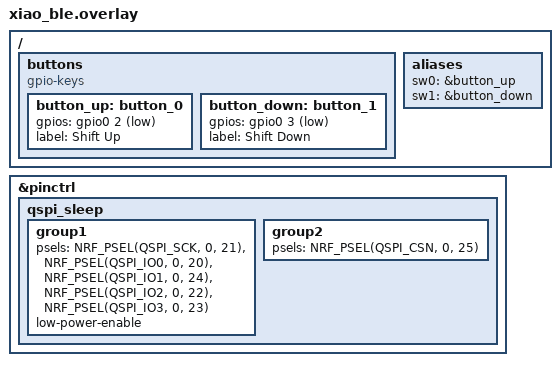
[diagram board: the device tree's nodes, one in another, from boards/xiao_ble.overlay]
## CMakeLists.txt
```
cmake_minimum_required(VERSION 3.20.0)
find_package(Zephyr REQUIRED HINTS $ENV{ZEPHYR_BASE})
project(nxs-controller)
target_sources(app PRIVATE
	src/main.c
	src/nxs_wireless_client.c
	src/debug_led.c
)
```

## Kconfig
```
menu "NXS Remote Application"

config APP_DEBUG_LED
	bool "Enable LED indication for shift command results (debug only)"
	default n
	help
	  シフトアップ/ダウンの成功・失敗をオンボードRGB LEDの点滅で示す。
	  GPIO操作が増えるため、省電力を優先する通常ビルドでは無効のままにする。

endmenu

source "Kconfig.zephyr"
```

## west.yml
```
manifest:
  remotes:
    - name: zephyrproject-rtos
      url-base: https://github.com/zephyrproject-rtos
  projects:
    - name: zephyr
      remote: zephyrproject-rtos
      revision: v4.4.2
      import: true
```

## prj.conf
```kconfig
CONFIG_GPIO=y

CONFIG_BT=y
CONFIG_BT_CENTRAL=y
CONFIG_BT_GATT_CLIENT=y
CONFIG_BT_MAX_CONN=1
CONFIG_BT_DEVICE_NAME="NXS-Cont"

CONFIG_POWEROFF=y
CONFIG_HWINFO=y
CONFIG_PM=y
CONFIG_PM_DEVICE=y

CONFIG_FLASH=y
```

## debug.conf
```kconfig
CONFIG_APP_DEBUG_LED=y
```

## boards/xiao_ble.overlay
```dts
#include <zephyr/dt-bindings/gpio/gpio.h>
#include <zephyr/dt-bindings/pinctrl/nrf-pinctrl.h>

/ {
	buttons {
		compatible = "gpio-keys";

		button_up: button_0 {
			gpios = <&gpio0 2 (GPIO_PULL_UP | GPIO_ACTIVE_LOW)>;
			label = "Shift Up";
		};

		button_down: button_1 {
			gpios = <&gpio0 3 (GPIO_PULL_UP | GPIO_ACTIVE_LOW)>;
			label = "Shift Down";
		};
	};

	aliases {
		sw0 = &button_up;
		sw1 = &button_down;
	};
};

&pinctrl {
    qspi_sleep: qspi_sleep {
        group1 {
            psels = <NRF_PSEL(QSPI_SCK, 0, 21)>,
                    <NRF_PSEL(QSPI_IO0, 0, 20)>,
                    <NRF_PSEL(QSPI_IO1, 0, 24)>,
                    <NRF_PSEL(QSPI_IO2, 0, 22)>,
                    <NRF_PSEL(QSPI_IO3, 0, 23)>;
            low-power-enable;
        };
        group2 {
            psels = <NRF_PSEL(QSPI_CSN, 0, 25)>;
        };
    };
};
```

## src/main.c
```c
#include <zephyr/kernel.h>
#include <zephyr/device.h>
#include <zephyr/drivers/gpio.h>
#include <zephyr/drivers/hwinfo.h>
#include <zephyr/pm/device.h>
#include <zephyr/sys/poweroff.h>
#include <zephyr/bluetooth/bluetooth.h>

#include "nxs_wireless_client.h"
#include "nxs_macaddr.h"
#include "debug_led.h"

#define NON_WAKEUP_RESET_REASON (RESET_PIN | RESET_SOFTWARE | RESET_POR | RESET_DEBUG)

static const struct gpio_dt_spec btn_up   = GPIO_DT_SPEC_GET(DT_ALIAS(sw0), gpios);
static const struct gpio_dt_spec btn_down = GPIO_DT_SPEC_GET(DT_ALIAS(sw1), gpios);

#if DT_NODE_EXISTS(DT_NODELABEL(p25q16h))
static const struct device *ext_flash = DEVICE_DT_GET(DT_NODELABEL(p25q16h));
#endif

static void arm_wakeup_and_poweroff(void)
{
    gpio_pin_configure_dt(&btn_up, GPIO_INPUT);
    gpio_pin_configure_dt(&btn_down, GPIO_INPUT);
    gpio_pin_interrupt_configure_dt(&btn_up, GPIO_INT_LEVEL_ACTIVE);
    gpio_pin_interrupt_configure_dt(&btn_down, GPIO_INT_LEVEL_ACTIVE);

#if DT_NODE_EXISTS(DT_NODELABEL(p25q16h))
    /* XIAOのオンボードQSPIフラッシュを明示的にディープパワーダウン。
       やらないとSystem OFF中も~1mA食われ続ける */
    if (device_is_ready(ext_flash)) {
        pm_device_action_run(ext_flash, PM_DEVICE_ACTION_SUSPEND);
    }
#endif

    hwinfo_clear_reset_cause();
    sys_poweroff();
}

int main(void)
{
    uint32_t reset_cause = 0;
    hwinfo_get_reset_cause(&reset_cause);

    if (reset_cause & NON_WAKEUP_RESET_REASON) {
        /* 書き込み直後・通常リセット。何もせずSystem OFFへ */
        arm_wakeup_and_poweroff();
        return 0;
    }

    /* GPIOによるSystem OFFからの復帰 = ボタン押下起床 */
    gpio_pin_configure_dt(&btn_up, GPIO_INPUT);
    gpio_pin_configure_dt(&btn_down, GPIO_INPUT);

    bool up   = gpio_pin_get_dt(&btn_up) > 0;
    bool down = gpio_pin_get_dt(&btn_down) > 0;

    if (up || down) {
        bt_enable(NULL);
        nxs_client_init(NXS_MAC, NXS_PIN);
        debug_led_init();

        int retry = 3;
        bool ok = false;
        while (retry-- && !ok) {
            ok = up ? nxs_connect_up_disconnect()
                     : nxs_connect_down_disconnect();
        }
        printk("shift %s: %s\n", up ? "up" : "down", ok ? "ok" : "failed");
        debug_led_shift_result(up, ok);
    }

    arm_wakeup_and_poweroff();
    return 0;
}
```

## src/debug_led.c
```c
#include "debug_led.h"

#if defined(CONFIG_APP_DEBUG_LED)

#include <zephyr/kernel.h>
#include <zephyr/drivers/gpio.h>

static const struct gpio_dt_spec led_red   = GPIO_DT_SPEC_GET(DT_ALIAS(led0), gpios);
static const struct gpio_dt_spec led_green = GPIO_DT_SPEC_GET(DT_ALIAS(led1), gpios);
static const struct gpio_dt_spec led_blue  = GPIO_DT_SPEC_GET(DT_ALIAS(led2), gpios);

void debug_led_init(void)
{
    gpio_pin_configure_dt(&led_red, GPIO_OUTPUT_INACTIVE);
    gpio_pin_configure_dt(&led_green, GPIO_OUTPUT_INACTIVE);
    gpio_pin_configure_dt(&led_blue, GPIO_OUTPUT_INACTIVE);
}

static void blink(const struct gpio_dt_spec *led, int times, int on_ms, int off_ms)
{
    for (int i = 0; i < times; i++) {
        gpio_pin_set_dt(led, 1);
        k_msleep(on_ms);
        gpio_pin_set_dt(led, 0);
        if (i + 1 < times) {
            k_msleep(off_ms);
        }
    }
}

void debug_led_shift_result(bool up, bool ok)
{
    if (!ok) {
        blink(&led_red, 3, 100, 100);   /* 失敗: 赤3回点滅（上下共通） */
        return;
    }
    /* 成功: 方向で色を分ける（アップ=緑、ダウン=青） */
    blink(up ? &led_green : &led_blue, 1, 300, 0);
}

#else /* !CONFIG_APP_DEBUG_LED */

void debug_led_init(void) {}
void debug_led_shift_result(bool up, bool ok) {}

#endif
```

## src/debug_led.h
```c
#pragma once
#include <stdbool.h>

void debug_led_init(void);
void debug_led_shift_result(bool up, bool ok);
```

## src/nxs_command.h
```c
#define BLE_CMD_GET_LIST 0x0000
#define BLE_CMD_ADD_DEVICE 0x0001
#define BLE_CMD_REMOVE_DEVICE 0x0002
#define BLE_CMD_SET_PIN 0x0003
#define BLE_CMD_BLINK_LED 0x0004
#define BLE_CMD_SET_BIKENET 0x0005
#define BLE_CMD_RESET_BIKENET 0x0006
#define BLE_CMD_DISCONNECT_DEVICE 0x0007
#define BLE_CMD_RECONNECT_DEVICE 0x0008   
#define BLE_CMD_SET_NAME 0x0009
#define BLE_CMD_CALIBRATE 0x000B
#define BLE_CMD_SET_DEV_CONFIG 0x000C
#define BLE_CMD_INCREMENT_MOVE 0x000D
#define BLE_CMD_ABSOLUTE_MOVE 0x000E
#define BLE_CMD_UPDATE_POSITION 0x000F
#define BLE_CMD_SHIFT_UP 0x0010
#define BLE_CMD_SHIFT_DOWN 0x0011
#define BLE_CMD_MOVE_TO_COG 0x0012
#define BLE_CMD_GET_POSITION 0x0013
#define BLE_CMD_WRITE_BUTTON_MAP 0x0014
#define BLE_CMD_READ_BUTTON_MAP 0x0015
#define BLE_CMD_SET_MOTOR_PARAMS 0x0016
#define BLE_CMD_GET_MOTOR_PARAMS 0x0017
#define BLE_CMD_GET_SKIP_TABLE 0x0018
#define BLE_CMD_MOTOR_HOME 0x0019
#define BLE_CMD_SET_SKIP_TABLE 0x001A
#define BLE_CMD_SET_FRONT_CONFIG 0x001B
#define BLE_CMD_GET_FRONT_CONFIG 0x001C
#define BLE_CMD_SET_REAR_COG_INFO 0x001D
#define BLE_CMD_SET_FRONT_COG_INFO 0x001E
#define BLE_CMD_GET_REAR_COG_INFO 0x001F
#define BLE_CMD_GET_FRONT_COG_INFO 0x0020
#define BLE_CMD_START_DFU 0x0021
#define BLE_CMD_SET_POD_BUTTON_V_LIST 0x0022
#define BLE_CMD_GET_POD_BUTTON_V_LIST 0x0023
#define BLE_CMD_GET_POD_BUTTON_LAST_V 0x0024
#define BLE_CMD_GET_FW_VER 0x0025
```

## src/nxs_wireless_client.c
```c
#include <zephyr/kernel.h>
#include <zephyr/bluetooth/bluetooth.h>
#include <zephyr/bluetooth/conn.h>
#include <zephyr/bluetooth/gatt.h>
#include <zephyr/bluetooth/uuid.h>
#include <zephyr/bluetooth/addr.h>
#include <string.h>
#include "nxs_wireless_client.h"

/*
 * NXS Wireless
 *   Service:              a5c1c000-cc20-ba91-0c1a-ef3f9e643d79
 *   Characteristic(auth):  a5c1cc02-cc20-ba91-0c1a-ef3f9e643d79
 *   Characteristic(ctrl):  a5c1cc01-cc20-ba91-0c1a-ef3f9e643d79
 *
 * ESP32-S3実装からの移植: 接続先(BlakBullet)に直接つなぎ、
 * 認証用キャラクタリスティックにPINを書き込んでから、
 * 制御用キャラクタリスティックにシフトコマンドを書き込む。
 * シフトコマンドの末尾6バイトは「接続先自身のMACアドレス」。
 */

#define BT_UUID_NXS_AUTH_VAL BT_UUID_128_ENCODE(0xa5c1cc02, 0xcc20, 0xba91, 0x0c1a, 0xef3f9e643d79)
#define BT_UUID_NXS_CTRL_VAL BT_UUID_128_ENCODE(0xa5c1cc01, 0xcc20, 0xba91, 0x0c1a, 0xef3f9e643d79)

static const struct bt_uuid_128 nxs_auth_uuid = BT_UUID_INIT_128(BT_UUID_NXS_AUTH_VAL);
static const struct bt_uuid_128 nxs_ctrl_uuid = BT_UUID_INIT_128(BT_UUID_NXS_CTRL_VAL);

static bt_addr_le_t peer_addr;
static uint8_t nxs_pin[4];
static uint8_t command_shift_up[8]   = {0x10, 0x00, 0, 0, 0, 0, 0, 0};
static uint8_t command_shift_down[8] = {0x11, 0x00, 0, 0, 0, 0, 0, 0};

static struct bt_conn *conn;
static uint16_t auth_handle, ctrl_handle;

static struct bt_gatt_discover_params disc_params;
static struct bt_gatt_write_params write_params;

static K_SEM_DEFINE(sem_connected, 0, 1);
static K_SEM_DEFINE(sem_disconnected, 0, 1);
static K_SEM_DEFINE(sem_discovered, 0, 1);
static K_SEM_DEFINE(sem_written, 0, 1);
static bool last_op_ok;

enum { DISC_AUTH, DISC_CTRL };
static int disc_target;

static uint8_t discover_cb(struct bt_conn *c, const struct bt_gatt_attr *attr,
                            struct bt_gatt_discover_params *params)
{
    if (attr) {
        struct bt_gatt_chrc *chrc = attr->user_data;
        if (disc_target == DISC_AUTH) {
            auth_handle = chrc->value_handle;
        } else {
            ctrl_handle = chrc->value_handle;
        }
        last_op_ok = true;
        return BT_GATT_ITER_STOP;
    }
    k_sem_give(&sem_discovered);
    return BT_GATT_ITER_STOP;
}

static bool discover_characteristic(const struct bt_uuid *uuid, int target)
{
    disc_target = target;
    last_op_ok = false;

    disc_params.uuid = uuid;
    disc_params.func = discover_cb;
    disc_params.start_handle = 0x0001;
    disc_params.end_handle = 0xffff;
    disc_params.type = BT_GATT_DISCOVER_CHARACTERISTIC;

    if (bt_gatt_discover(conn, &disc_params)) {
        return false;
    }
    k_sem_take(&sem_discovered, K_SECONDS(5));
    return last_op_ok;
}

static void write_cb(struct bt_conn *c, uint8_t err, struct bt_gatt_write_params *params)
{
    last_op_ok = (err == 0);
    k_sem_give(&sem_written);
}

static bool gatt_write(uint16_t handle, const uint8_t *data, size_t len)
{
    if (!handle) {
        return false;
    }
    write_params.func = write_cb;
    write_params.handle = handle;
    write_params.offset = 0;
    write_params.data = data;
    write_params.length = len;

    if (bt_gatt_write(conn, &write_params)) {
        return false;
    }
    k_sem_take(&sem_written, K_SECONDS(5));
    return last_op_ok;
}

static void connected_cb(struct bt_conn *c, uint8_t err)
{
    last_op_ok = (err == 0);
    k_sem_give(&sem_connected);
}

static void disconnected_cb(struct bt_conn *c, uint8_t reason)
{
    k_sem_give(&sem_disconnected);
}

BT_CONN_CB_DEFINE(nxs_conn_cbs) = {
    .connected = connected_cb,
    .disconnected = disconnected_cb,
};

void nxs_client_init(const char *peer_address_str, const uint8_t pin[4])
{
    bt_addr_le_from_str(peer_address_str, "random", &peer_addr);

    memcpy(&command_shift_up[2], peer_addr.a.val, 6);
    memcpy(&command_shift_down[2], peer_addr.a.val, 6);
    memcpy(nxs_pin, pin, 4);
}

bool nxs_connect(void)
{
    auth_handle = 0;
    ctrl_handle = 0;

    if (bt_conn_le_create(&peer_addr, BT_CONN_LE_CREATE_CONN, BT_LE_CONN_PARAM_DEFAULT, &conn)) {
        return false;
    }

    k_sem_take(&sem_connected, K_SECONDS(5));
    if (!last_op_ok) {
        conn = NULL;
        return false;
    }

    if (!discover_characteristic(&nxs_auth_uuid.uuid, DISC_AUTH)) goto fail;
    if (!gatt_write(auth_handle, nxs_pin, sizeof(nxs_pin))) goto fail;
    if (!discover_characteristic(&nxs_ctrl_uuid.uuid, DISC_CTRL)) goto fail;

    return true;

fail:
    nxs_disconnect();
    return false;
}

bool nxs_disconnect(void)
{
    if (!conn) {
        return true;
    }
    bt_conn_disconnect(conn, BT_HCI_ERR_REMOTE_USER_TERM_CONN);
    k_sem_take(&sem_disconnected, K_SECONDS(5));
    bt_conn_unref(conn);
    conn = NULL;
    return true;
}

bool nxs_up(void)   { return gatt_write(ctrl_handle, command_shift_up, sizeof(command_shift_up)); }
bool nxs_down(void) { return gatt_write(ctrl_handle, command_shift_down, sizeof(command_shift_down)); }

bool nxs_connect_up_disconnect(void)
{
    if (!nxs_connect()) return false;
    bool ok = nxs_up();
    nxs_disconnect();
    return ok;
}

bool nxs_connect_down_disconnect(void)
{
    if (!nxs_connect()) return false;
    bool ok = nxs_down();
    nxs_disconnect();
    return ok;
}
```

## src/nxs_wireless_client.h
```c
#pragma once
#include <stdint.h>
#include <stdbool.h>

void nxs_client_init(const char *peer_address_str, const uint8_t pin[4]);

bool nxs_connect(void);
bool nxs_disconnect(void);
bool nxs_up(void);
bool nxs_down(void);

bool nxs_connect_up_disconnect(void);
bool nxs_connect_down_disconnect(void);
```
